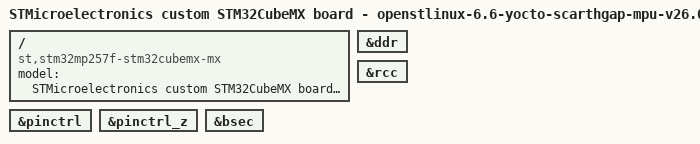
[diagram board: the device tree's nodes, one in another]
// SPDX-License-Identifier: (GPL-2.0-only OR BSD-3-Clause)
/*
 * Copyright (C) 2026, STMicroelectronics - All Rights Reserved
 * Author: STM32CubeMX code generation for STMicroelectronics.
 */

/* For more information on Device Tree configuration, please refer to
 * https://wiki.st.com/stm32mpu/wiki/Category:Device_tree_configuration
 */

/dts-v1/;

#include <dt-bindings/pinctrl/stm32-pinfunc.h>
#include <dt-bindings/clock/stm32mp25-clksrc.h>

#include "stm32mp257.dtsi"
#include "stm32mp25xf.dtsi"
#include "stm32mp257f-stm32cubemx-mx-rcc.dtsi"
#include "stm32mp25xxak-pinctrl.dtsi"
/* !!! log : Warning - DDR not configured: unknown DDR dtsi  !!! */
/*#include "???-ddr.dtsi"*/

/* USER CODE BEGIN includes */
/* USER CODE END includes */

/ {
	model = "STMicroelectronics custom STM32CubeMX board - openstlinux-6.6-yocto-scarthgap-mpu-v26.02.18";
	compatible = "st,stm32mp257f-stm32cubemx-mx", "st,stm32mp257";

	/* !!! log : Warning - no DDR config found: 'memory' node not generated  !!! */

	/*
	memory@??? {
		reg = < ??? >;
	};
	*/

	/* USER CODE BEGIN root */
	/* USER CODE END root */

}; /*root*/

&pinctrl {
	/* USER CODE BEGIN pinctrl */
	/* USER CODE END pinctrl */
};

&pinctrl_z {
	/* USER CODE BEGIN pinctrl_z */
	/* USER CODE END pinctrl_z */
};

&bsec {
	status = "okay";

	/* USER CODE BEGIN bsec */
	/* USER CODE END bsec */
};

&ddr {
	status = "okay";

	/* USER CODE BEGIN ddr */
	/* USER CODE END ddr */
};

&rcc {
	status = "okay";

	/* USER CODE BEGIN rcc */
	/* USER CODE END rcc */
};

/* USER CODE BEGIN addons */
/* USER CODE END addons */

